# pse84_a0 register map
Vendor: Infineon Technologies; Series: PSE84_A0; File version: 1.0
CPU: CM33 r0p1, little endian, MPU, FPU, VTOR, 3 interrupt priority bits
Registers are 32-bit, read-write, reset 0x0 unless marked. A register's access mark holds for its fields unless they carry their own. Offsets are from the block's base; [hi:lo] are bit positions.

## ETH0 (part 1 of 3) — Ethernet Interface
Base 0x42C10000
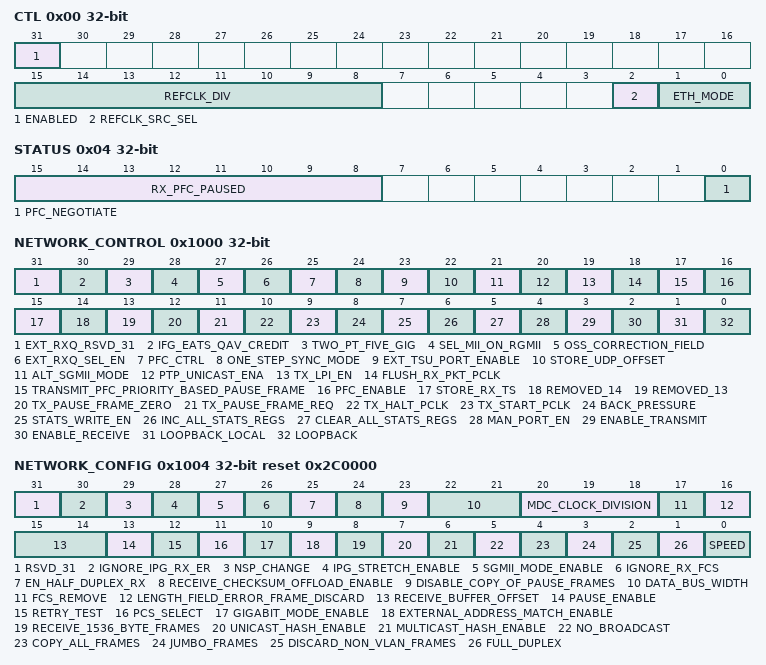
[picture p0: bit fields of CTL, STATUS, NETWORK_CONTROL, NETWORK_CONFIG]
0x00 CTL — EMAC Control Register
  [31] ENABLED — EMAC enable: '0': Disabled. '1': Enabled.
  [15:8] REFCLK_DIV — Specify the reference clock divider. Integer division by (1+REFCLK_DIV). Allows for integer divisions in the range [1, 256].
  [2] REFCLK_SRC_SEL — Select the source for reference clock. 0: Reference clock comes from ref_clk input port (HSIO). 1: Reference clock comes from an internal clock source (PLL).
  [1:0] ETH_MODE — Set ethernet mode. The speed of 10M/100M/1G is selected by programming NETWORK_CONFIG after IP is enabled. The field also specifies the clock source of internal transmit clock and receive clock domain.
    0=MII (MII mode (10/100MHz speed is determined by NETWORK_CONFIG[0]).); 1=GMII (GMII mode (NETWORK_CONFIG[10] must be set to enable 1G operation).); 2=RGMII (RGMII mode (10M/100M/1G speed is determined by NETWORK_CONFIG[10] and NETWORK_CONFIG[0]).); 3=RMII (RMII mode (10M/100M speed is determined by NETWORK_CONFIG[0]).)
0x04 STATUS ro — EMAC Status Register
  [15:8] RX_PFC_PAUSED — Each bit corresponds to a priority indicated within the PFC priority based pause frame. Each bit is set when a PFC priority based pause frame has been received, and the associated priority pause time quantum is non-zero. Each bit is cleared when the associated pause time identified by the received pause time quantum has elapsed.
  [0] PFC_NEGOTIATE — Identifies that PFC priority based pause flow control has been negotiated. 0 - No PFC priority based pause frames have yet been received, flow control is being handled using classic 802.3 pause frames. 1 - At least one PFC priority based pause frames has been received. All subsequent 802.3 pause frames will be dropped.
0x1000 NETWORK_CONTROL — The network control register contains general MAC control functions for both receiver and transmitter.
  [31] EXT_RXQ_RSVD_31 ro
  [30] IFG_EATS_QAV_CREDIT
  [29] TWO_PT_FIVE_GIG
  [28] SEL_MII_ON_RGMII
  [27] OSS_CORRECTION_FIELD
  [26] EXT_RXQ_SEL_EN — Enable external selection of receive queue. When this bit is high the ext_match1, ext_match2, ext_match3 and ext_match4 inputs will determine which receive queue a frame is routed to. This will be the case regardless of the state of the external address match enable bit 9 of the network config register. Note that receive frames will be dropped unless they are matched by the internal frame filtering functionality. If the external address match enable bit 9 in the network config register is set frames may be matched by an external address match filter as long as one of the ext_match1, ext_match2, ext_match3 and ext_match4 inputs is asserted early enough. When set EXT_RXQ_SEL_EN takes precedence over the existing screener functionality. This bit is only relevant if priority queuing is configured. Note: ext_match1, ext_match2, ext_match_3 and ext_match4 inputs are fixed to 0 internally.
  [25] PFC_CTRL
  [24] ONE_STEP_SYNC_MODE
  [23] EXT_TSU_PORT_ENABLE ro
  [22] STORE_UDP_OFFSET
  [21] ALT_SGMII_MODE
  [20] PTP_UNICAST_ENA
  [19] TX_LPI_EN
  [18] FLUSH_RX_PKT_PCLK wo
  [17] TRANSMIT_PFC_PRIORITY_BASED_PAUSE_FRAME wo
  [16] PFC_ENABLE
  [15] STORE_RX_TS
  [14] REMOVED_14 ro
  [13] REMOVED_13 ro
  [12] TX_PAUSE_FRAME_ZERO wo
  [11] TX_PAUSE_FRAME_REQ wo
  [10] TX_HALT_PCLK wo
  [9] TX_START_PCLK wo
  [8] BACK_PRESSURE
  [7] STATS_WRITE_EN
  [6] INC_ALL_STATS_REGS wo
  [5] CLEAR_ALL_STATS_REGS wo
  [4] MAN_PORT_EN
  [3] ENABLE_TRANSMIT
  [2] ENABLE_RECEIVE
  [1] LOOPBACK_LOCAL — Not used.
  [0] LOOPBACK — Not used.
0x1004 NETWORK_CONFIG reset 0x2C0000 — The network configuration register contains functions for setting the mode of operation for the Gigabit Ethernet MAC.
  [31] RSVD_31
  [30] IGNORE_IPG_RX_ER — Ignore IPG rx_er. When set rx_er has no effect on the GEMs operation when rx_ctl is low. Set this when using the RGMII wrapper in half-duplex mode.
  [29] NSP_CHANGE
  [28] IPG_STRETCH_ENABLE
  [27] SGMII_MODE_ENABLE
  [26] IGNORE_RX_FCS
  [25] EN_HALF_DUPLEX_RX — Enable frames to be received in half-duplex mode while transmitting.
  [24] RECEIVE_CHECKSUM_OFFLOAD_ENABLE
  [23] DISABLE_COPY_OF_PAUSE_FRAMES — Disable copy of pause frames - set to one to prevent pause frames being copied to memory. When set, neither control frames with type id 8808, nor pause frames with destination address 010000c28001 are copied to memory. Note that valid pause frames received will still increment pause statistics and pause the transmission of frames as required.
  [22:21] DATA_BUS_WIDTH — Data bus width - set according to AMBA (AXI/AHB) or external FIFO data bus width. Only valid bus widths may be written if the system is configured to a maximum width less than 128-bits. 00: 32 bit data bus width 01: 64 bit AMBA (AXI/AHB) data bus width 10: 128 bit AMBA (AXI/AHB) data bus width 11: 128 bit AMBA (AXI/AHB) data bus width. Note: When AXI interface for DMA access is supported, EMAC only supports 64b DMA data bus width, so must set it 1. When AHB interface for DMA access is supported, EMAC only supports 32b DMA data bus width, so must set it 0. (See TRM feature list for AXI/AHB interface)
  [20:18] MDC_CLOCK_DIVISION — MDC clock division - set according to clk_sys speed. These three bits determine the number clk_sys will be divided by to generate MDC. For conformance with the 802.3 specification, MDC must not exceed 2.5 MHz (MDC is only active during MDIO read and write operations). 000: divide clk_sys by 8 (clk_sys up to 20 MHz) 001: divide clk_sys by 16 (clk_sys up to 40 MHz) 010: divide clk_sys by 32 (clk_sys up to 80 MHz) 011: divide clk_sys by 48 (clk_sys up to 120MHz) 100: divide clk_sys by 64 (clk_sys up to 160 MHz) 101: divide clk_sys by 96 (clk_sys up to 240 MHz) 110: divide clk_sys by 128 (clk_sys up to 320 MHz) 111: divide clk_sys by 224 (clk_sys up to 540 MHz).
  [17] FCS_REMOVE
  [16] LENGTH_FIELD_ERROR_FRAME_DISCARD
  [15:14] RECEIVE_BUFFER_OFFSET
  [13] PAUSE_ENABLE
  [12] RETRY_TEST — Retry test - must be set to zero for normal operation. If set to one the backoff between collisions will always be one slot time. Setting this bit to one helps test the too many retries condition. Also used in the pause frame tests to reduce the pause counter's decrement time from 512 bit times, to every receive clock cycle.
  [11] PCS_SELECT
  [10] GIGABIT_MODE_ENABLE
  [9] EXTERNAL_ADDRESS_MATCH_ENABLE
  [8] RECEIVE_1536_BYTE_FRAMES
  [7] UNICAST_HASH_ENABLE
  [6] MULTICAST_HASH_ENABLE
  [5] NO_BROADCAST
  [4] COPY_ALL_FRAMES
  [3] JUMBO_FRAMES — Jumbo frames - set to one to enable jumbo frames up to 10,240 bytes to be accepted. The default length is 10,240 bytes.
  [2] DISCARD_NON_VLAN_FRAMES
  [1] FULL_DUPLEX — Full duplex - if set to logic one, the transmit block ignores the state of collision and carrier sense and allows receive while transmitting.
  [0] SPEED
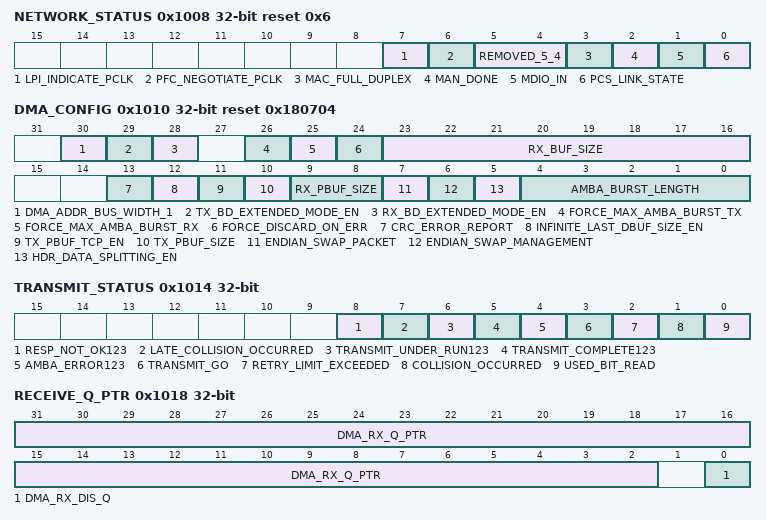
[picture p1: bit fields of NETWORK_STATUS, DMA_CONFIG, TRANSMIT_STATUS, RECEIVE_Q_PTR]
0x1008 NETWORK_STATUS ro reset 0x6 — The network status register returns status information with respect to the PHY management interface.
  [7] LPI_INDICATE_PCLK
  [6] PFC_NEGOTIATE_PCLK
  [5:4] REMOVED_5_4
  [3] MAC_FULL_DUPLEX
  [2] MAN_DONE
  [1] MDIO_IN — Returns status of the mdio pin.
  [0] PCS_LINK_STATE
0x100C USER_IO_REGISTER ro — Not presents. Access to the register will return AHB error.
  [31:0] RSVD_31_0 — Write ignore, read 0
0x1010 DMA_CONFIG reset 0x180704 — DMA Configuration Register
  [30] DMA_ADDR_BUS_WIDTH_1 — DMA address bus width. 0 = 32b, 1 = 64b. Note: EMAC only supports 32b DMA address bus width, so must set it 0.
  [29] TX_BD_EXTENDED_MODE_EN
  [28] RX_BD_EXTENDED_MODE_EN
  [26] FORCE_MAX_AMBA_BURST_TX
  [25] FORCE_MAX_AMBA_BURST_RX
  [24] FORCE_DISCARD_ON_ERR
  [23:16] RX_BUF_SIZE — DMA receive buffer size in external AMBA (AXI/AHB) system memory. The value defined by these bits determines the size of buffer to use in main system memory when writing received data. The value is defined in multiples of 64 bytes. 0x01 corresponds to buffers of 64 bytes 0x02 corresponds to 128 bytes etc. For example: 0x02: 128 byte. 0x18: 1536 byte (1*max length frame/buffer) 0xA0: 10240 byte (1*10K jumbo frame/buffer) Note that this value should never be written as zero.
  [13] CRC_ERROR_REPORT
  [12] INFINITE_LAST_DBUF_SIZE_EN
  [11] TX_PBUF_TCP_EN
  [10] TX_PBUF_SIZE
  [9:8] RX_PBUF_SIZE
  [7] ENDIAN_SWAP_PACKET — endian swap mode enable for packet data accesses. When set, selects swapped endianism for AMBA (AXI/AHB) transfers. When clear, selects little endian mode.
  [6] ENDIAN_SWAP_MANAGEMENT — endian swap mode enable for management descriptor accesses. When set, selects swapped endianism for AMBA (AXI/AHB) transfers. When clear, selects little endian mode.
  [5] HDR_DATA_SPLITTING_EN — Enable header data Splitting. When set, receive frames will be forwarded to main memory using a minimum of two DMA data buffers. The first X data buffers will contain the frame header, consisting of the Ethernet,VLAN,(IPv4 or IPv6),(TCP or UDP). X= (frame header size divided by RX_BUF_SIZE as defined in bits 23:16 of this register). The last Y data buffers will contain the frame payload. Y= (frame payload size divided by RX_BUF_SIZE). Note that for non VLAN/IP/TCP/UDP frames, the header will always be 14 bytes. When this feature is disabled, the frame is forwarded to main memory in blocks of RX_BUF_SIZE. Note: This feature can only be set when AXI interface for DMA access is used. (See TRM feature list for AXI/AHB interface)
  [4:0] AMBA_BURST_LENGTH — Selects the burst length to use on the AMBA (AHB/AXI) when transferring frame data. Not used for DMA management operations and only used where space and data size allow and respecting AXI/AHB burst boundary rules. One-hot priority encoding enforced automatically on register writes as follows, where x represents don't care: 1xxxx: Attempt to use bursts of up to 16. 01xxx: Attempt to use bursts of up to 8. 001xx: Attempt to use bursts of up to 4. 0001x: Always use SINGLE bursts. 00001: Always use SINGLE bursts. 00000: Attempt to use bursts of up to 256. Note: EMAC only supports burst length up to 16.
0x1014 TRANSMIT_STATUS — This register, when read, provides details of the status of a transmit. Once read, individual bits may be cleared by writing 1 to them. It is not possible to set a bit to 1 by writing to the register.
  [8] RESP_NOT_OK123 — bresp/hresp not OK - set when BRESP (AXI write response) or HRESP (AHB read/write response) is detected as not OK on AXI/AHB interface for DMA access. Cleared by writing a one to this bit.
  [7] LATE_COLLISION_OCCURRED
  [6] TRANSMIT_UNDER_RUN123
  [5] TRANSMIT_COMPLETE123
  [4] AMBA_ERROR123 — Transmit frame corruption due to AMBA (AXI/AHB) errors. Set if an error occurs whilst midway through reading transmit frame from external memory including HRESP (read/write response on AHB interface for DMA access), RRESP or BRESP (read/write response on AXI interface for DMA access) errors and buffers exhausted mid frame (if the buffers run out during transmission of a frame then transmission stops, FCS shall be bad and tx_er asserted). Also set in DMA packet buffer mode if single frame is too large for configured packet buffer memory size. Cleared by writing a one to this bit.
  [3] TRANSMIT_GO ro
  [2] RETRY_LIMIT_EXCEEDED
  [1] COLLISION_OCCURRED
  [0] USED_BIT_READ
0x1018 RECEIVE_Q_PTR — This register holds the start address of the receive buffer queue (receive buffers descriptor list). The receive buffer queue base address must be initialized before receive is enabled through bit 2 of the network control register. Once reception is enabled, any write to the receive buffer queue base address register is ignored. Reading this register returns the location of the descriptor currently being accessed. This value increments as buffers are used. Software should not use this register for determining where to remove received frames from the queue as it constantly changes as new frames are received. Software should instead work its way through the buffer descriptor queue checking the used bits. In terms of AMBA (AXI) operation, the receive descriptors are read from memory using a single 32bit AXI access. When the datapath is configured at 64bit, the receive descriptors should be aligned at 64-bit boundaries and each pair of 32-bit descriptors is written to using a single 64bit AXI access.
  [31:2] DMA_RX_Q_PTR — Receive buffer queue base address - written with the address of the start of the receive queue.
  [0] DMA_RX_DIS_Q — Disable queue if set to 1. This can be used to reduce the number of active queues and should only be changed while receive is not enabled.
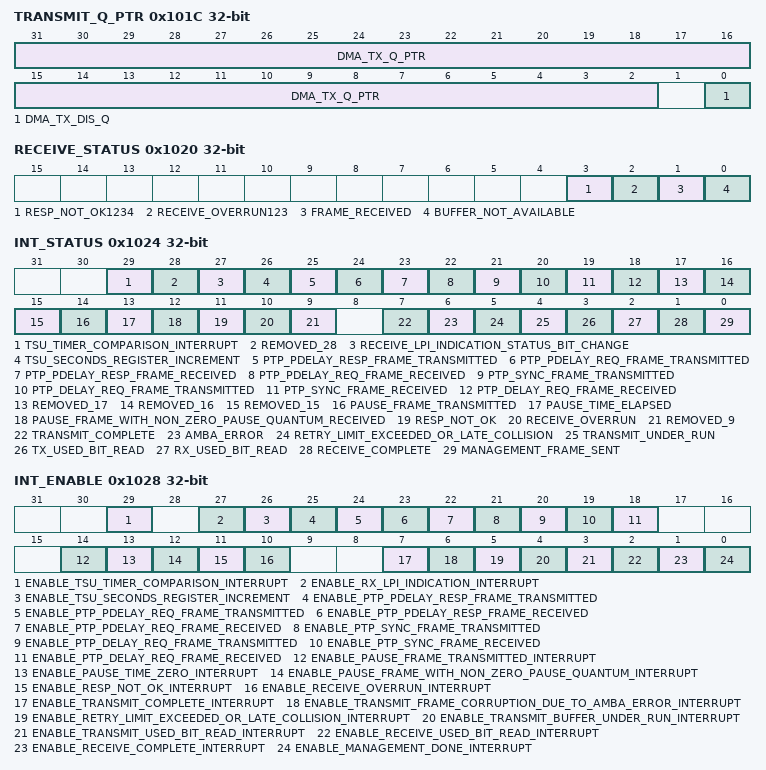
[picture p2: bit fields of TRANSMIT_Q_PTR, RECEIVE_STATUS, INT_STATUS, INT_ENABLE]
0x101C TRANSMIT_Q_PTR — This register holds the start address of the transmit buffer queue (transmit buffers descriptor list). The transmit buffer queue base address register must be initialized before transmit is started through bit 9 of the network control register. Once transmission has started, any write to the transmit buffer queue base address register is illegal and therefore ignored. Note that due to clock boundary synchronization, it takes a maximum of four pclk cycles from the writing of the transmit start bit before the transmitter is active. Writing to the transmit buffer queue base address register during this time may produce unpredictable results. Reading this register returns the location of the descriptor currently being accessed. Because the DMA can store data for multiple frames at once, this may not necessarily be pointing to the current frame being transmitted. In terms of AMBA AXI operation, the transmit descriptors are written to memory using a single 32bit AHB access. When the datapath is configured as 64bit, the transmit descriptors should be aligned at 64-bit boundaries and each pair of 32-bit descriptors is read from memory using a single AXI access.
  [31:2] DMA_TX_Q_PTR — Transmit buffer queue base address - written with the address of the start of the transmit queue.
  [0] DMA_TX_DIS_Q — Disable queue if set to 1. This can be used to reduce the number of active queues and should only be changed while transmit is not enabled.
0x1020 RECEIVE_STATUS — This register, when read provides details of the status of a receive. Once read, individual bits may be cleared by writing 1 to them. It is not possible to set a bit to 1 by writing to the register.
  [3] RESP_NOT_OK1234 — bresp/hresp not OK - set when BRESP (AXI write response) or HRESP (AHB read/write response) is detected as not OK on AXI/AHB interface for DMA access. Cleared by writing a one to this bit.
  [2] RECEIVE_OVERRUN123
  [1] FRAME_RECEIVED
  [0] BUFFER_NOT_AVAILABLE
0x1024 INT_STATUS — If not configured for priority queueing, the GEM generates a single interrupt. This register indicates the source of this interrupt. The corresponding bit in the mask register must be clear for a bit to be set. If any bit is set in this register the ethernet_int signal will be asserted. For test purposes each bit can be set or reset by writing to the interrupt mask register. The default configuration is shown below whereby all bits are reset to zero on read. Changing the validity of the `gem_irq_read_clear define will instead require a one to be written to the appropriate bit in order to clear it. In this mode reading has no affect on the status of the bit.
  [29] TSU_TIMER_COMPARISON_INTERRUPT wo
  [28] REMOVED_28 ro
  [27] RECEIVE_LPI_INDICATION_STATUS_BIT_CHANGE wo
  [26] TSU_SECONDS_REGISTER_INCREMENT wo
  [25] PTP_PDELAY_RESP_FRAME_TRANSMITTED wo
  [24] PTP_PDELAY_REQ_FRAME_TRANSMITTED wo
  [23] PTP_PDELAY_RESP_FRAME_RECEIVED wo
  [22] PTP_PDELAY_REQ_FRAME_RECEIVED wo
  [21] PTP_SYNC_FRAME_TRANSMITTED wo
  [20] PTP_DELAY_REQ_FRAME_TRANSMITTED wo
  [19] PTP_SYNC_FRAME_RECEIVED wo
  [18] PTP_DELAY_REQ_FRAME_RECEIVED wo
  [17] REMOVED_17 ro
  [16] REMOVED_16 ro
  [15] REMOVED_15 ro
  [14] PAUSE_FRAME_TRANSMITTED wo — Pause frame transmitted - indicates a pause frame has been successfully transmitted after being initiated from the network control register. Cleared on read.
  [13] PAUSE_TIME_ELAPSED wo
  [12] PAUSE_FRAME_WITH_NON_ZERO_PAUSE_QUANTUM_RECEIVED wo
  [11] RESP_NOT_OK wo — bresp/hresp not OK - set when BRESP (AXI write response) or HRESP (AHB read/write response) is detected as not OK on AXI/AHB interface for DMA access. Cleared on read.
  [10] RECEIVE_OVERRUN wo
  [9] REMOVED_9 ro
  [7] TRANSMIT_COMPLETE wo
  [6] AMBA_ERROR
  [5] RETRY_LIMIT_EXCEEDED_OR_LATE_COLLISION
  [4] TRANSMIT_UNDER_RUN — Transmit under run - this interrupt is set if the transmitter was forced to terminate a frame that it has already began transmitting due to further data being unavailable. If an under run occurs, the transmitter will force bad crc and tx_er high. This interrupt is set if a transmitter status write back has not completed when another status write back is attempted. When using the DMA interface configured for internal FIFO mode, this interrupt is also set when the transmit DMA has written the SOP data into the FIFO and either the AHB bus was not granted in time for further data, or because an AHB/AXI error response was returned by the connected slave, or because a used bit was read. When using the DMA interface configured for packet buffer mode, this bit will never be set. Cleared on read.
  [3] TX_USED_BIT_READ
  [2] RX_USED_BIT_READ
  [1] RECEIVE_COMPLETE
  [0] MANAGEMENT_FRAME_SENT
0x1028 INT_ENABLE wo — At reset all interrupts are disabled. Writing a one to the relevant bit location enables the required interrupt. This register is write only and when read will return zero.
  [29] ENABLE_TSU_TIMER_COMPARISON_INTERRUPT
  [27] ENABLE_RX_LPI_INDICATION_INTERRUPT
  [26] ENABLE_TSU_SECONDS_REGISTER_INCREMENT
  [25] ENABLE_PTP_PDELAY_RESP_FRAME_TRANSMITTED
  [24] ENABLE_PTP_PDELAY_REQ_FRAME_TRANSMITTED
  [23] ENABLE_PTP_PDELAY_RESP_FRAME_RECEIVED
  [22] ENABLE_PTP_PDELAY_REQ_FRAME_RECEIVED
  [21] ENABLE_PTP_SYNC_FRAME_TRANSMITTED
  [20] ENABLE_PTP_DELAY_REQ_FRAME_TRANSMITTED
  [19] ENABLE_PTP_SYNC_FRAME_RECEIVED
  [18] ENABLE_PTP_DELAY_REQ_FRAME_RECEIVED
  [14] ENABLE_PAUSE_FRAME_TRANSMITTED_INTERRUPT
  [13] ENABLE_PAUSE_TIME_ZERO_INTERRUPT
  [12] ENABLE_PAUSE_FRAME_WITH_NON_ZERO_PAUSE_QUANTUM_INTERRUPT
  [11] ENABLE_RESP_NOT_OK_INTERRUPT — Enable bresp/hresp not OK interrupt
  [10] ENABLE_RECEIVE_OVERRUN_INTERRUPT
  [7] ENABLE_TRANSMIT_COMPLETE_INTERRUPT
  [6] ENABLE_TRANSMIT_FRAME_CORRUPTION_DUE_TO_AMBA_ERROR_INTERRUPT — Enable transmit frame corruption due to AMBA (AXI/AHB) error interrupt
  [5] ENABLE_RETRY_LIMIT_EXCEEDED_OR_LATE_COLLISION_INTERRUPT
  [4] ENABLE_TRANSMIT_BUFFER_UNDER_RUN_INTERRUPT
  [3] ENABLE_TRANSMIT_USED_BIT_READ_INTERRUPT
  [2] ENABLE_RECEIVE_USED_BIT_READ_INTERRUPT
  [1] ENABLE_RECEIVE_COMPLETE_INTERRUPT
  [0] ENABLE_MANAGEMENT_DONE_INTERRUPT
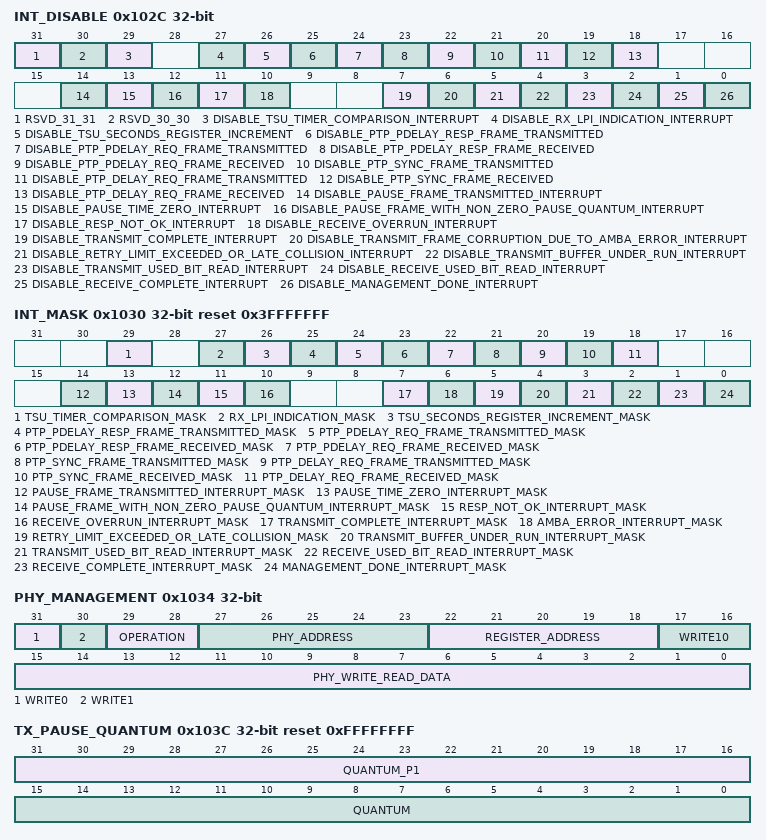
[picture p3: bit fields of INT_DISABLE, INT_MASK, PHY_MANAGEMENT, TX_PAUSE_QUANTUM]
0x102C INT_DISABLE — Writing a 1 to the relevant bit location disables that particular interrupt. This register is write only and when read will return zero.
  [31] RSVD_31_31 ro
  [30] RSVD_30_30 ro
  [29] DISABLE_TSU_TIMER_COMPARISON_INTERRUPT wo
  [27] DISABLE_RX_LPI_INDICATION_INTERRUPT wo
  [26] DISABLE_TSU_SECONDS_REGISTER_INCREMENT wo
  [25] DISABLE_PTP_PDELAY_RESP_FRAME_TRANSMITTED wo
  [24] DISABLE_PTP_PDELAY_REQ_FRAME_TRANSMITTED wo
  [23] DISABLE_PTP_PDELAY_RESP_FRAME_RECEIVED wo
  [22] DISABLE_PTP_PDELAY_REQ_FRAME_RECEIVED wo
  [21] DISABLE_PTP_SYNC_FRAME_TRANSMITTED wo
  [20] DISABLE_PTP_DELAY_REQ_FRAME_TRANSMITTED wo
  [19] DISABLE_PTP_SYNC_FRAME_RECEIVED wo
  [18] DISABLE_PTP_DELAY_REQ_FRAME_RECEIVED wo
  [14] DISABLE_PAUSE_FRAME_TRANSMITTED_INTERRUPT wo
  [13] DISABLE_PAUSE_TIME_ZERO_INTERRUPT wo
  [12] DISABLE_PAUSE_FRAME_WITH_NON_ZERO_PAUSE_QUANTUM_INTERRUPT wo
  [11] DISABLE_RESP_NOT_OK_INTERRUPT wo — 'Disable bresp/hresp not OK interrupt'
  [10] DISABLE_RECEIVE_OVERRUN_INTERRUPT wo
  [7] DISABLE_TRANSMIT_COMPLETE_INTERRUPT wo
  [6] DISABLE_TRANSMIT_FRAME_CORRUPTION_DUE_TO_AMBA_ERROR_INTERRUPT wo — 'Disable transmit frame corruption due to AMBA (AHB/AXI) error interrupt'
  [5] DISABLE_RETRY_LIMIT_EXCEEDED_OR_LATE_COLLISION_INTERRUPT wo
  [4] DISABLE_TRANSMIT_BUFFER_UNDER_RUN_INTERRUPT wo
  [3] DISABLE_TRANSMIT_USED_BIT_READ_INTERRUPT wo
  [2] DISABLE_RECEIVE_USED_BIT_READ_INTERRUPT wo
  [1] DISABLE_RECEIVE_COMPLETE_INTERRUPT wo
  [0] DISABLE_MANAGEMENT_DONE_INTERRUPT wo
0x1030 INT_MASK ro reset 0x3FFFFFFF — The interrupt mask register is a read only register indicating which interrupts are masked. All bits are set at reset and can be reset individually by writing to the interrupt enable register or set individually by writing to the interrupt disable register. Having separate address locations for enable and disable saves the need for performing a read modify write when updating the interrupt mask register. For test purposes there is a write-only function to this register that allows the bits in the interrupt status register to be set or cleared, regardless of the state of the mask register.
  [29] TSU_TIMER_COMPARISON_MASK — Enable TSU timer comparison interrupt mask.
  [27] RX_LPI_INDICATION_MASK — A read of this register returns the value of the RX LPI indication mask. 0: Interrupt is enabled. 1: Interrupt is disabled. A write to this register directly affects the state of the corresponding bit in the interrupt status register, causing an interrupt to be generated if a 1 is written
  [26] TSU_SECONDS_REGISTER_INCREMENT_MASK — A read of this register returns the value of the TSU seconds register increment mask. 0: Interrupt is enabled. 1: Interrupt is disabled. A write to this register directly affects the state of the corresponding bit in the interrupt status register, causing an interrupt to be generated if a 1 is written.
  [25] PTP_PDELAY_RESP_FRAME_TRANSMITTED_MASK — A read of this register returns the value of the PTP pdelay_resp frame transmitted mask. 0: Interrupt is enabled. 1: Interrupt is disabled. A write to this register directly affects the state of the corresponding bit in the interrupt status register, causing an interrupt to be generated if a 1 is written.
  [24] PTP_PDELAY_REQ_FRAME_TRANSMITTED_MASK — A read of this register returns the value of the PTP pdelay_req frame transmitted mask. 0: Interrupt is enabled. 1: Interrupt is disabled. A write to this register directly affects the state of the corresponding bit in the interrupt status register, causing an interrupt to be generated if a 1 is written.
  [23] PTP_PDELAY_RESP_FRAME_RECEIVED_MASK — A read of this register returns the value of the PTP pdelay_resp frame received mask. 0: Interrupt is enabled. 1: Interrupt is disabled. A write to this register directly affects the state of the corresponding bit in the interrupt status register, causing an interrupt to be generated if a 1 is written.
  [22] PTP_PDELAY_REQ_FRAME_RECEIVED_MASK — A read of this register returns the value of the PTP pdelay_req frame received mask. 0: Interrupt is enabled. 1: Interrupt is disabled. A write to this register directly affects the state of the corresponding bit in the interrupt status register, causing an interrupt to be generated if a 1 is written.
  [21] PTP_SYNC_FRAME_TRANSMITTED_MASK — A read of this register returns the value of the PTP sync frame transmitted mask. 0: Interrupt is enabled. 1: Interrupt is disabled. A write to this register directly affects the state of the corresponding bit in the interrupt status register, causing an interrupt to be generated if a 1 is written.
  [20] PTP_DELAY_REQ_FRAME_TRANSMITTED_MASK — A read of this register returns the value of the PTP delay_req frame transmitted mask. 0: Interrupt is enabled. 1: Interrupt is disabled. A write to this register directly affects the state of the corresponding bit in the interrupt status register, causing an interrupt to be generated if a 1 is written.
  [19] PTP_SYNC_FRAME_RECEIVED_MASK — A read of this register returns the value of the PTP sync frame received mask. 0: Interrupt is enabled. 1: Interrupt is disabled. A write to this register directly affects the state of the corresponding bit in the interrupt status register, causing an interrupt to be generated if a 1 is written.
  [18] PTP_DELAY_REQ_FRAME_RECEIVED_MASK — A read of this register returns the value of the PTP delay_req frame received mask. 0: Interrupt is enabled. 1: Interrupt is disabled. A write to this register directly affects the state of the corresponding bit in the interrupt status register, causing an interrupt to be generated if a 1 is written.
  [14] PAUSE_FRAME_TRANSMITTED_INTERRUPT_MASK — pause frame transmitted interrupt mask. 0: Interrupt is enabled. 1: Interrupt is disabled. A write to this register directly affects the state of the corresponding bit in the interrupt status register, causing an interrupt to be generated if a 1 is written.
  [13] PAUSE_TIME_ZERO_INTERRUPT_MASK — pause time zero interrupt mask. 0: Interrupt is enabled. 1: Interrupt is disabled. A write to this register directly affects the state of the corresponding bit in the interrupt status register, causing an interrupt to be generated if a 1 is written.
  [12] PAUSE_FRAME_WITH_NON_ZERO_PAUSE_QUANTUM_INTERRUPT_MASK — pause frame with non-zero pause quantum interrupt mask. 0: Interrupt is enabled. 1: Interrupt is disabled. A write to this register directly affects the state of the corresponding bit in the interrupt status register, causing an interrupt to be generated if a 1 is written.
  [11] RESP_NOT_OK_INTERRUPT_MASK — bresp not OK interrupt mask. 0: Interrupt is enabled. 1: Interrupt is disabled. A write to this register directly affects the state of the corresponding bit in the interrupt status register, causing an interrupt to be generated if a 1 is written.
  [10] RECEIVE_OVERRUN_INTERRUPT_MASK — receive overrun interrupt mask. 0: Interrupt is enabled. 1: Interrupt is disabled. A write to this register directly affects the state of the corresponding bit in the interrupt status register, causing an interrupt to be generated if a 1 is written.
  [7] TRANSMIT_COMPLETE_INTERRUPT_MASK — transmit complete interrupt mask. 0: Interrupt is enabled. 1: Interrupt is disabled. A write to this register directly affects the state of the corresponding bit in the interrupt status register, causing an interrupt to be generated if a 1 is written.
  [6] AMBA_ERROR_INTERRUPT_MASK — transmit frame corruption due to AMBA (AXI/AHB) error interrupt mask. 0: Interrupt is enabled. 1: Interrupt is disabled. A write to this register directly affects the state of the corresponding bit in the interrupt status register, causing an interrupt to be generated if a 1 is written.
  [5] RETRY_LIMIT_EXCEEDED_OR_LATE_COLLISION_MASK — A read of this register returns the value of the retry limit exceeded or late collision (gigabit mode only) interrupt mask. 0: Interrupt is enabled. 1: Interrupt is disabled. A write to this register directly affects the state of the corresponding bit in the interrupt status register, causing an interrupt to be generated if a 1 is written.
  [4] TRANSMIT_BUFFER_UNDER_RUN_INTERRUPT_MASK — transmit buffer under run interrupt mask. 0: Interrupt is enabled. 1: Interrupt is disabled. A write to this register directly affects the state of the corresponding bit in the interrupt status register, causing an interrupt to be generated if a 1 is written.
  [3] TRANSMIT_USED_BIT_READ_INTERRUPT_MASK — transmit used bit read interrupt mask. 0: Interrupt is enabled. 1: Interrupt is disabled. A write to this register directly affects the state of the corresponding bit in the interrupt status register, causing an interrupt to be generated if a 1 is written.
  [2] RECEIVE_USED_BIT_READ_INTERRUPT_MASK — receive used bit read interrupt mask. 0: Interrupt is enabled. 1: Interrupt is disabled. A write to this register directly affects the state of the corresponding bit in the interrupt status register, causing an interrupt to be generated if a 1 is written.
  [1] RECEIVE_COMPLETE_INTERRUPT_MASK — receive complete interrupt mask. 0: Interrupt is enabled. 1: Interrupt is disabled. A write to this register directly affects the state of the corresponding bit in the interrupt status register, causing an interrupt to be generated if a 1 is written.
  [0] MANAGEMENT_DONE_INTERRUPT_MASK — management done interrupt mask. 0: Interrupt is enabled. 1: Interrupt is disabled. A write to this register directly affects the state of the corresponding bit in the interrupt status register, causing an interrupt to be generated if a 1 is written.
0x1034 PHY_MANAGEMENT — The PHY maintenance register is implemented as a shift register. Writing to the register starts a shift operation which is signalled as complete when bit-2 is set in the network status register. It takes about 2000 pclk cycles to complete, when MDC is set for pclk divide by 32 in the network configuration register. An interrupt is generated upon completion. During this time, the MSB of the register is output on the MDIO pin and the LSB updated from the MDIO pin with each MDC cycle. This causes transmission of a PHY management frame on MDIO. See Section 22.2.4.5 of the IEEE 802.3 standard. Reading during the shift operation will return the current contents of the shift register. At the end of management operation, the bits will have shifted back to their original locations. For a read operation, the data bits will be updated with data read from the PHY. It is important to write the correct values to the register to ensure a valid PHY management frame is produced. The MDIO interface can read IEEE 802.3 clause 45 PHYs as well as clause 22 PHYs. To read clause 45 PHYs, bit 30 should be written with a 0 rather than a 1. For a description of MDC generation, see Network Configuration Register.
  [31] WRITE0 — Must be written with 0.
  [30] WRITE1 — Must be written to 1 for a valid Clause 22 frame and to 0 for a valid Clause 45 frame.
  [29:28] OPERATION — Operation. For a Clause 45 frame: 00 is an addr, 01 is a write, 10 is a post read increment, 11 is a read frame. For a Clause 22 frame: 10 is a read, 01 is a write.
  [27:23] PHY_ADDRESS
  [22:18] REGISTER_ADDRESS — Register address - specifies the register in the PHY to access.
  [17:16] WRITE10 — Must be written with 10.
  [15:0] PHY_WRITE_READ_DATA — For a write operation this is written with the data to be written to the PHY. After a read operation this contains the data read from the PHY.
0x1038 PAUSE_TIME ro — Received Pause Quantum Register
  [15:0] QUANTUM — Received pause quantum - stores the current value of the received pause quantum register which is decremented every 512 bit times.
0x103C TX_PAUSE_QUANTUM reset 0xFFFFFFFF — Transmit Pause Quantum Register
  [31:16] QUANTUM_P1 — Transmit pause quantum - written with the pause quantum value for pause frame transmission of priority 1.
  [15:0] QUANTUM — Transmit pause quantum - written with the pause quantum value for pause frame transmission.
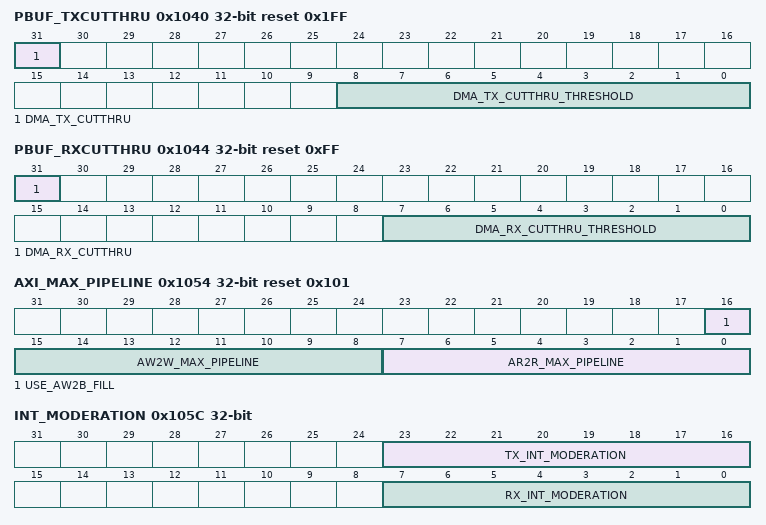
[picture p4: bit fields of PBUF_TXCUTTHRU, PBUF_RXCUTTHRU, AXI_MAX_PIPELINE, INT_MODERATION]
0x1040 PBUF_TXCUTTHRU reset 0x1FF — Partial store and forward is only applicable when using the DMA configured in SRAM based packet buffer mode. It is also not available when using multi buffer frames. TX Partial Store and Forward
  [31] DMA_TX_CUTTHRU
  [8:0] DMA_TX_CUTTHRU_THRESHOLD — Watermark value. This value must be >= 0x9.
0x1044 PBUF_RXCUTTHRU reset 0xFF — RX Partial Store and Forward
  [31] DMA_RX_CUTTHRU
  [7:0] DMA_RX_CUTTHRU_THRESHOLD — Watermark value.
0x1048 JUMBO_MAX_LENGTH reset 0x600 — Maximum Jumbo Frame Size.
  [13:0] JUMBO_MAX_LENGTH — Maximum Jumbo Frame Size
0x104C EXTERNAL_FIFO_INTERFACE ro — Not presents.
  [31:0] REMOVED_31_0 — Write ignore, read 0
0x1054 AXI_MAX_PIPELINE reset 0x101 — Used to set the maximum amount of outstanding transactions on the AXI bus between AR / R channels and AW / W channels. Cannot be more than the depth of the configured AXI pipeline FIFO (defined in verilog defs.v)
  [16] USE_AW2B_FILL — For the write issuing capability as defined in bits 15:8 of this register, select whether the max number of transactions operates between the AW to W AXI channel or the AW to B channel. Set to 0 to operate between the AW and W channels. Set to 1 to operate between the AW and B channels.
  [15:8] AW2W_MAX_PIPELINE — Defines the maximum number of outstanding AXI write requests that can be issued by the DMA via the AW channel.
  [7:0] AR2R_MAX_PIPELINE — Defines the maximum number of outstanding AXI read requests that can be issued by the DMA via the AR channel.
0x1058 RSC_CONTROL ro — Not presents. Access to the register will return AHB error.
  [31:0] REMOVED_31_0 — Write ignore, read 0
0x105C INT_MODERATION — Used to moderate the number of transmit and receive complete interrupts issued. With interrupt moderation enabled receive and transmit interrupts are not generated immediately a frame is transmitted or received. Instead when a receive or transmit event occurs a timer is started and the interrupt is asserted after it times out. This limits the frequency with which the CPU receives interrupts. When interrupt moderation is enabled interrupt status bit one is always used for receive and bit 7 is always used for transmit even when priority queuing is enabled. With interrupt moderation 800ns periods are counted. GEM determines what constitutes an 800ns period by looking at the tbi (bit 11), gigabit bit (10) and speed (bit 0) bits in the network configuration register and counting tx_clk cycles. Bit 0 needs to be set to 1 for 100M operation.
  [23:16] TX_INT_MODERATION — Count of 800ns periods before bit 7 is set in the interrupt status register after a frame is transmitted. A non-zero value indicates transmit interrupt moderation will be performed.
  [7:0] RX_INT_MODERATION — Count of 800ns periods before bit 1 is set in the interrupt status register after a frame is received. A non-zero value indicates receive interrupt moderation will be performed.
0x1060 SYS_WAKE_TIME — Used to pause transmission after deassertion of tx_lpi_en. Each unit in this register corresponds to 64ns in gigabit mode, 320ns in 100M mode and 3200ns at 10M. After tx_lpi_en is deasserted transmission will pause for the set time.
  [15:0] SYS_WAKE_TIME — Count of 64ns, 320ns or 3200ns intervals before transmission starts after deassertion of TX_LPI_EN bit field (each interval is equivalent to eight transmit clock periods and so varies with data rate) in the network control register.
0x1080 HASH_BOTTOM — The unicast hash enable and the multicast hash enable bits in the network configuration register enable the reception of hash matched frames. Hash Register Bottom (31 to 0 bits)
  [31:0] ADDRESS_HASH_B — The first 32 bits of the hash address register.
0x1084 HASH_TOP — Hash Register Top (63 to 32 bits)
  [31:0] ADDRESS_HASH_T — The remaining 32 bits of the hash address register.
0x1088 SPEC_ADD1_BOTTOM — The addresses stored in the specific address registers are deactivated at reset or when their corresponding specific address register bottom is written. They are activated when specific address register top is written.
  [31:0] ADDRESS_ADD1_B — 'Least significant 32 bits of the destination address, that is bits 31:0. Bit zero indicates whether the address is multicast or unicast and corresponds to the least significant bit of the first byte received.'
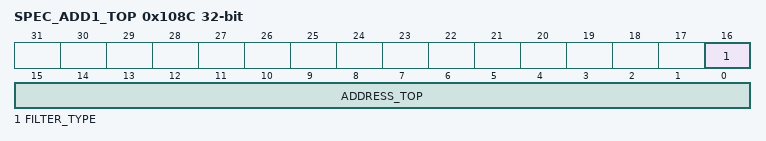
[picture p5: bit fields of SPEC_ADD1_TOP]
0x108C SPEC_ADD1_TOP — Specific Address Top
  [16] FILTER_TYPE — This control bit selects whether this filter should be comparing the MAC source address or the MAC destination address of the received Ethernet frame. When set to zero, the filter is a destination address filter. When set to one, the filter is a source address filter. Specific address 1. The most significant bits of the destination address, that is bits 47:32.
  [15:0] ADDRESS_TOP — Specific address 1. The most significant bits of the destination/source address that is to be compared, that is bits 47:32.
